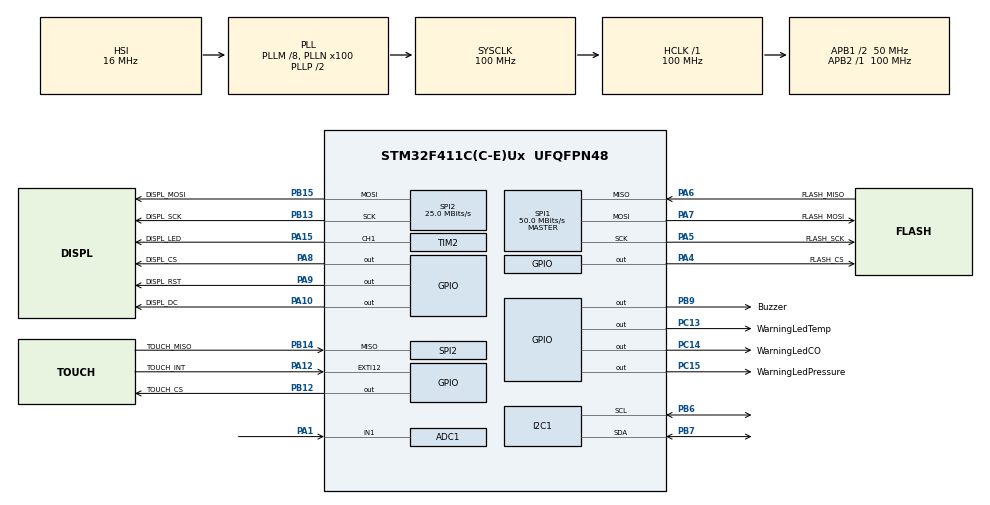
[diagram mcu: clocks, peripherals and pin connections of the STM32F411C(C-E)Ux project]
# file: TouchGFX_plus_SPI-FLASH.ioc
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ADC1.Channel-0\#ChannelRegularConversion=ADC_CHANNEL_1
ADC1.NbrOfConversionFlag=1
ADC1.Rank-0\#ChannelRegularConversion=1
ADC1.SamplingTime-0\#ChannelRegularConversion=ADC_SAMPLETIME_3CYCLES
ADC1.master=1
Dma.Request0=SPI2_TX
Dma.SPI2_TX.0.Direction=DMA_MEMORY_TO_PERIPH
Dma.SPI2_TX.0.FIFOMode=DMA_FIFOMODE_DISABLE
Dma.SPI2_TX.0.Instance=DMA1_Stream4
Dma.SPI2_TX.0.MemDataAlignment=DMA_MDATAALIGN_BYTE
Dma.SPI2_TX.0.MemInc=DMA_MINC_ENABLE
Dma.SPI2_TX.0.Mode=DMA_NORMAL
Dma.SPI2_TX.0.PeriphDataAlignment=DMA_PDATAALIGN_BYTE
Dma.SPI2_TX.0.PeriphInc=DMA_PINC_DISABLE
Dma.SPI2_TX.0.Priority=DMA_PRIORITY_LOW
Mcu.Family=STM32F4
Mcu.Name=STM32F411C(C-E)Ux
Mcu.Package=UFQFPN48
NVIC.DMA1_Stream4_IRQn=true\:0\:0\:false\:false\:true\:false\:true\:true
NVIC.EXTI15_10_IRQn=true\:0\:0\:false\:false\:true\:true\:true\:true
NVIC.PriorityGroup=NVIC_PRIORITYGROUP_4
NVIC.SPI2_IRQn=true\:0\:0\:false\:false\:true\:true\:true\:true
NVIC.TIM3_IRQn=true\:0\:0\:false\:false\:true\:true\:true\:true
PA1.Signal=ADCx_IN1
PA10.GPIO_Label=DISPL_DC
PA10.GPIO_Speed=GPIO_SPEED_FREQ_HIGH
PA10.Signal=GPIO_Output
PA12.GPIO_Label=TOUCH_INT
PA12.Signal=GPXTI12
PA13.Mode=Serial_Wire
PA13.Signal=SYS_JTMS-SWDIO
PA14.Mode=Serial_Wire
PA14.Signal=SYS_JTCK-SWCLK
PA15.GPIO_Label=DISPL_LED
PA15.Signal=S_TIM2_CH1_ETR
PA4.GPIO_Label=FLASH_CS
PA4.GPIO_Speed=GPIO_SPEED_FREQ_HIGH
PA4.PinState=GPIO_PIN_SET
PA4.Signal=GPIO_Output
PA5.GPIO_Label=FLASH_SCK
PA5.Mode=Full_Duplex_Master
PA5.Signal=SPI1_SCK
PA6.GPIO_Label=FLASH_MISO
PA6.Mode=Full_Duplex_Master
PA6.Signal=SPI1_MISO
PA7.GPIO_Label=FLASH_MOSI
PA7.Mode=Full_Duplex_Master
PA7.Signal=SPI1_MOSI
PA8.GPIO_Label=DISPL_CS
PA8.GPIO_Speed=GPIO_SPEED_FREQ_HIGH
PA8.PinState=GPIO_PIN_SET
PA8.Signal=GPIO_Output
PA9.GPIO_Label=DISPL_RST
PA9.GPIO_Speed=GPIO_SPEED_FREQ_LOW
PA9.PinState=GPIO_PIN_RESET
PA9.Signal=GPIO_Output
PB12.GPIO_Label=TOUCH_CS
PB12.GPIO_Speed=GPIO_SPEED_FREQ_HIGH
PB12.PinState=GPIO_PIN_SET
PB12.Signal=GPIO_Output
PB13.GPIO_Label=DISPL_SCK
PB13.Mode=Full_Duplex_Master
PB13.Signal=SPI2_SCK
PB14.GPIO_Label=TOUCH_MISO
PB14.Mode=Full_Duplex_Master
PB14.Signal=SPI2_MISO
PB15.GPIO_Label=DISPL_MOSI
PB15.Mode=Full_Duplex_Master
PB15.Signal=SPI2_MOSI
PB6.Mode=I2C
PB6.Signal=I2C1_SCL
PB7.Mode=I2C
PB7.Signal=I2C1_SDA
PB9.GPIO_Label=Buzzer
PB9.Signal=GPIO_Output
PC13-ANTI_TAMP.GPIO_Label=WarningLedTemp
PC13-ANTI_TAMP.Signal=GPIO_Output
PC14-OSC32_IN.GPIO_Label=WarningLedCO
PC14-OSC32_IN.Signal=GPIO_Output
PC15-OSC32_OUT.GPIO_Label=WarningLedPressure
PC15-OSC32_OUT.Signal=GPIO_Output
PH0\ -\ OSC_IN.Mode=HSE-External-Oscillator
PH0\ -\ OSC_IN.Signal=RCC_OSC_IN
PH1\ -\ OSC_OUT.Mode=HSE-External-Oscillator
PH1\ -\ OSC_OUT.Signal=RCC_OSC_OUT
ProjectManager.HeapSize=0x200
ProjectManager.StackSize=0x400
ProjectManager.TargetToolchain=STM32CubeIDE
RCC.48MHZClocksFreq_Value=50000000
RCC.AHBFreq_Value=100000000
RCC.APB1CLKDivider=RCC_HCLK_DIV2
RCC.APB1Freq_Value=50000000
RCC.APB1TimFreq_Value=100000000
RCC.APB2Freq_Value=100000000
RCC.APB2TimFreq_Value=100000000
RCC.CortexFreq_Value=100000000
RCC.HCLKFreq_Value=100000000
RCC.HSE_VALUE=25000000
RCC.HSI_VALUE=16000000
RCC.LSE_VALUE=32768
RCC.PLLM=8
RCC.PLLN=100
RCC.SYSCLKFreq_VALUE=100000000
RCC.SYSCLKSource=RCC_SYSCLKSOURCE_PLLCLK
RCC.VCOOutputFreq_Value=200000000
SH.ADCx_IN1.0=ADC1_IN1,IN1
SH.S_TIM2_CH1_ETR.0=TIM2_CH1,PWM Generation1 CH1
SPI1.CalculateBaudRate=50.0 MBits/s
SPI1.Direction=SPI_DIRECTION_2LINES
SPI1.Mode=SPI_MODE_MASTER
SPI1.VirtualType=VM_MASTER
SPI2.CalculateBaudRate=25.0 MBits/s
SPI2.Direction=SPI_DIRECTION_2LINES
SPI2.Mode=SPI_MODE_MASTER
SPI2.VirtualType=VM_MASTER
STMicroelectronics.X-CUBE-TOUCHGFX.4.22.0.ApplicationCcGraphicsJjApplication=TouchGFXOoGenerator
STMicroelectronics.X-CUBE-TOUCHGFX.4.22.0.tgfx_buffering_strategy=Partial
STMicroelectronics.X-CUBE-TOUCHGFX.4.22.0.tgfx_custom_height=240
STMicroelectronics.X-CUBE-TOUCHGFX.4.22.0.tgfx_custom_width=320
STMicroelectronics.X-CUBE-TOUCHGFX.4.22.0.tgfx_datareader=Enabled
STMicroelectronics.X-CUBE-TOUCHGFX.4.22.0.tgfx_datareader_mem_size=16777216
STMicroelectronics.X-CUBE-TOUCHGFX.4.22.0_IsPackSelfContextualization=true
TIM2.Channel-PWM\ Generation1\ CH1=TIM_CHANNEL_1
TIM2.Period=100
TIM2.Prescaler=1000
TIM3.Period=100
TIM3.Prescaler=13333
VP_CRC_VS_CRC.Mode=CRC_Activate
VP_STMicroelectronics.X-CUBE-TOUCHGFX_VS_GraphicsJjApplication_4.22.0.Mode=GraphicsJjApplication
VP_TIM3_VS_ClockSourceINT.Mode=Internal
board=custom

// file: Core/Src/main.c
/* USER CODE BEGIN Header */
/**
  ******************************************************************************
  * @file           : main.c
  * @brief          : Main program body
  ******************************************************************************
  * @attention
  *
  * Copyright (c) 2023 STMicroelectronics.
  * All rights reserved.
  *
  * This software is licensed under terms that can be found in the LICENSE file
  * in the root directory of this software component.
  * If no LICENSE file comes with this software, it is provided AS-IS.
  *
  ******************************************************************************
  */
/* USER CODE END Header */
#include "main.h"
#include "app_touchgfx.h"

ADC_HandleTypeDef hadc1;

CRC_HandleTypeDef hcrc;

I2C_HandleTypeDef hi2c1;

SPI_HandleTypeDef hspi1;
SPI_HandleTypeDef hspi2;
DMA_HandleTypeDef hdma_spi2_tx;

TIM_HandleTypeDef htim2;
TIM_HandleTypeDef htim3;

void SystemClock_Config(void);
static void MX_GPIO_Init(void);
static void MX_DMA_Init(void);
static void MX_CRC_Init(void);
static void MX_SPI1_Init(void);
static void MX_SPI2_Init(void);
static void MX_TIM2_Init(void);
static void MX_TIM3_Init(void);
static void MX_ADC1_Init(void);
static void MX_I2C1_Init(void);

int main(void)
{

  /* MCU Configuration--------------------------------------------------------*/

  /* Reset of all peripherals, Initializes the Flash interface and the Systick. */
  HAL_Init();

  /* Configure the system clock */
  SystemClock_Config();

  /* Initialize all configured peripherals */
  MX_GPIO_Init();
  MX_DMA_Init();
  MX_CRC_Init();
  MX_SPI1_Init();
  MX_SPI2_Init();
  MX_TIM2_Init();
  MX_TIM3_Init();
  MX_ADC1_Init();
  MX_I2C1_Init();
  MX_TouchGFX_Init();
  /* USER CODE BEGIN 2 */
  Displ_Init(Displ_Orientat_0);			// initialize display controller - set orientation parameter as per TouchGFX setup
  Displ_BackLight('I');  					// initialize backlight
  HAL_TIM_Base_Start_IT(&TGFX_T);			// start TouchGFX tick timer

  /* USER CODE END 2 */

  /* Infinite loop */
  while (1)
  {

  MX_TouchGFX_Process();
  }
}

void SystemClock_Config(void)
{
  RCC_OscInitTypeDef RCC_OscInitStruct = {0};
  RCC_ClkInitTypeDef RCC_ClkInitStruct = {0};

  /** Configure the main internal regulator output voltage
  */
  __HAL_RCC_PWR_CLK_ENABLE();
  __HAL_PWR_VOLTAGESCALING_CONFIG(PWR_REGULATOR_VOLTAGE_SCALE1);

  /** Initializes the RCC Oscillators according to the specified parameters
  * in the RCC_OscInitTypeDef structure.
  */
  RCC_OscInitStruct.OscillatorType = RCC_OSCILLATORTYPE_HSI;
  RCC_OscInitStruct.HSIState = RCC_HSI_ON;
  RCC_OscInitStruct.HSICalibrationValue = RCC_HSICALIBRATION_DEFAULT;
  RCC_OscInitStruct.PLL.PLLState = RCC_PLL_ON;
  RCC_OscInitStruct.PLL.PLLSource = RCC_PLLSOURCE_HSI;
  RCC_OscInitStruct.PLL.PLLM = 8;
  RCC_OscInitStruct.PLL.PLLN = 100;
  RCC_OscInitStruct.PLL.PLLP = RCC_PLLP_DIV2;
  RCC_OscInitStruct.PLL.PLLQ = 4;
  if (HAL_RCC_OscConfig(&RCC_OscInitStruct) != HAL_OK)
  {
    Error_Handler();
  }

  /** Initializes the CPU, AHB and APB buses clocks
  */
  RCC_ClkInitStruct.ClockType = RCC_CLOCKTYPE_HCLK|RCC_CLOCKTYPE_SYSCLK
                              |RCC_CLOCKTYPE_PCLK1|RCC_CLOCKTYPE_PCLK2;
  RCC_ClkInitStruct.SYSCLKSource = RCC_SYSCLKSOURCE_PLLCLK;
  RCC_ClkInitStruct.AHBCLKDivider = RCC_SYSCLK_DIV1;
  RCC_ClkInitStruct.APB1CLKDivider = RCC_HCLK_DIV2;
  RCC_ClkInitStruct.APB2CLKDivider = RCC_HCLK_DIV1;

  if (HAL_RCC_ClockConfig(&RCC_ClkInitStruct, FLASH_LATENCY_3) != HAL_OK)
  {
    Error_Handler();
  }
}

static void MX_ADC1_Init(void)
{

  ADC_ChannelConfTypeDef sConfig = {0};

  /** Configure the global features of the ADC (Clock, Resolution, Data Alignment and number of conversion)
  */
  hadc1.Instance = ADC1;
  hadc1.Init.ClockPrescaler = ADC_CLOCK_SYNC_PCLK_DIV4;
  hadc1.Init.Resolution = ADC_RESOLUTION_12B;
  hadc1.Init.ScanConvMode = DISABLE;
  hadc1.Init.ContinuousConvMode = DISABLE;
  hadc1.Init.DiscontinuousConvMode = DISABLE;
  hadc1.Init.ExternalTrigConvEdge = ADC_EXTERNALTRIGCONVEDGE_NONE;
  hadc1.Init.ExternalTrigConv = ADC_SOFTWARE_START;
  hadc1.Init.DataAlign = ADC_DATAALIGN_RIGHT;
  hadc1.Init.NbrOfConversion = 1;
  hadc1.Init.DMAContinuousRequests = DISABLE;
  hadc1.Init.EOCSelection = ADC_EOC_SINGLE_CONV;
  if (HAL_ADC_Init(&hadc1) != HAL_OK)
  {
    Error_Handler();
  }

  /** Configure for the selected ADC regular channel its corresponding rank in the sequencer and its sample time.
  */
  sConfig.Channel = ADC_CHANNEL_1;
  sConfig.Rank = 1;
  sConfig.SamplingTime = ADC_SAMPLETIME_3CYCLES;
  if (HAL_ADC_ConfigChannel(&hadc1, &sConfig) != HAL_OK)
  {
    Error_Handler();
  }

}

static void MX_CRC_Init(void)
{

  hcrc.Instance = CRC;
  if (HAL_CRC_Init(&hcrc) != HAL_OK)
  {
    Error_Handler();
  }

}

static void MX_I2C1_Init(void)
{

  hi2c1.Instance = I2C1;
  hi2c1.Init.ClockSpeed = 100000;
  hi2c1.Init.DutyCycle = I2C_DUTYCYCLE_2;
  hi2c1.Init.OwnAddress1 = 0;
  hi2c1.Init.AddressingMode = I2C_ADDRESSINGMODE_7BIT;
  hi2c1.Init.DualAddressMode = I2C_DUALADDRESS_DISABLE;
  hi2c1.Init.OwnAddress2 = 0;
  hi2c1.Init.GeneralCallMode = I2C_GENERALCALL_DISABLE;
  hi2c1.Init.NoStretchMode = I2C_NOSTRETCH_DISABLE;
  if (HAL_I2C_Init(&hi2c1) != HAL_OK)
  {
    Error_Handler();
  }

}

static void MX_SPI1_Init(void)
{

  /* SPI1 parameter configuration*/
  hspi1.Instance = SPI1;
  hspi1.Init.Mode = SPI_MODE_MASTER;
  hspi1.Init.Direction = SPI_DIRECTION_2LINES;
  hspi1.Init.DataSize = SPI_DATASIZE_8BIT;
  hspi1.Init.CLKPolarity = SPI_POLARITY_LOW;
  hspi1.Init.CLKPhase = SPI_PHASE_1EDGE;
  hspi1.Init.NSS = SPI_NSS_SOFT;
  hspi1.Init.BaudRatePrescaler = SPI_BAUDRATEPRESCALER_2;
  hspi1.Init.FirstBit = SPI_FIRSTBIT_MSB;
  hspi1.Init.TIMode = SPI_TIMODE_DISABLE;
  hspi1.Init.CRCCalculation = SPI_CRCCALCULATION_DISABLE;
  hspi1.Init.CRCPolynomial = 10;
  if (HAL_SPI_Init(&hspi1) != HAL_OK)
  {
    Error_Handler();
  }

}

static void MX_SPI2_Init(void)
{

  /* SPI2 parameter configuration*/
  hspi2.Instance = SPI2;
  hspi2.Init.Mode = SPI_MODE_MASTER;
  hspi2.Init.Direction = SPI_DIRECTION_2LINES;
  hspi2.Init.DataSize = SPI_DATASIZE_8BIT;
  hspi2.Init.CLKPolarity = SPI_POLARITY_LOW;
  hspi2.Init.CLKPhase = SPI_PHASE_1EDGE;
  hspi2.Init.NSS = SPI_NSS_SOFT;
  hspi2.Init.BaudRatePrescaler = SPI_BAUDRATEPRESCALER_2;
  hspi2.Init.FirstBit = SPI_FIRSTBIT_MSB;
  hspi2.Init.TIMode = SPI_TIMODE_DISABLE;
  hspi2.Init.CRCCalculation = SPI_CRCCALCULATION_DISABLE;
  hspi2.Init.CRCPolynomial = 10;
  if (HAL_SPI_Init(&hspi2) != HAL_OK)
  {
    Error_Handler();
  }

}

static void MX_TIM2_Init(void)
{

  TIM_MasterConfigTypeDef sMasterConfig = {0};
  TIM_OC_InitTypeDef sConfigOC = {0};

  htim2.Instance = TIM2;
  htim2.Init.Prescaler = 1000;
  htim2.Init.CounterMode = TIM_COUNTERMODE_UP;
  htim2.Init.Period = 100;
  htim2.Init.ClockDivision = TIM_CLOCKDIVISION_DIV1;
  htim2.Init.AutoReloadPreload = TIM_AUTORELOAD_PRELOAD_DISABLE;
  if (HAL_TIM_PWM_Init(&htim2) != HAL_OK)
  {
    Error_Handler();
  }
  sMasterConfig.MasterOutputTrigger = TIM_TRGO_RESET;
  sMasterConfig.MasterSlaveMode = TIM_MASTERSLAVEMODE_DISABLE;
  if (HAL_TIMEx_MasterConfigSynchronization(&htim2, &sMasterConfig) != HAL_OK)
  {
    Error_Handler();
  }
  sConfigOC.OCMode = TIM_OCMODE_PWM1;
  sConfigOC.Pulse = 0;
  sConfigOC.OCPolarity = TIM_OCPOLARITY_HIGH;
  sConfigOC.OCFastMode = TIM_OCFAST_DISABLE;
  if (HAL_TIM_PWM_ConfigChannel(&htim2, &sConfigOC, TIM_CHANNEL_1) != HAL_OK)
  {
    Error_Handler();
  }
  HAL_TIM_MspPostInit(&htim2);

}

static void MX_TIM3_Init(void)
{

  TIM_ClockConfigTypeDef sClockSourceConfig = {0};
  TIM_MasterConfigTypeDef sMasterConfig = {0};

  htim3.Instance = TIM3;
  htim3.Init.Prescaler = 13333;
  htim3.Init.CounterMode = TIM_COUNTERMODE_UP;
  htim3.Init.Period = 100;
  htim3.Init.ClockDivision = TIM_CLOCKDIVISION_DIV1;
  htim3.Init.AutoReloadPreload = TIM_AUTORELOAD_PRELOAD_DISABLE;
  if (HAL_TIM_Base_Init(&htim3) != HAL_OK)
  {
    Error_Handler();
  }
  sClockSourceConfig.ClockSource = TIM_CLOCKSOURCE_INTERNAL;
  if (HAL_TIM_ConfigClockSource(&htim3, &sClockSourceConfig) != HAL_OK)
  {
    Error_Handler();
  }
  sMasterConfig.MasterOutputTrigger = TIM_TRGO_RESET;
  sMasterConfig.MasterSlaveMode = TIM_MASTERSLAVEMODE_DISABLE;
  if (HAL_TIMEx_MasterConfigSynchronization(&htim3, &sMasterConfig) != HAL_OK)
  {
    Error_Handler();
  }

}

static void MX_DMA_Init(void)
{

  /* DMA controller clock enable */
  __HAL_RCC_DMA1_CLK_ENABLE();

  /* DMA interrupt init */
  /* DMA1_Stream4_IRQn interrupt configuration */
  HAL_NVIC_SetPriority(DMA1_Stream4_IRQn, 0, 0);
  HAL_NVIC_EnableIRQ(DMA1_Stream4_IRQn);

}

static void MX_GPIO_Init(void)
{
  GPIO_InitTypeDef GPIO_InitStruct = {0};

  /* GPIO Ports Clock Enable */
  __HAL_RCC_GPIOC_CLK_ENABLE();
  __HAL_RCC_GPIOH_CLK_ENABLE();
  __HAL_RCC_GPIOA_CLK_ENABLE();
  __HAL_RCC_GPIOB_CLK_ENABLE();

  /*Configure GPIO pin Output Level */
  HAL_GPIO_WritePin(GPIOC, WarningLedTemp_Pin|WarningLedCO_Pin|WarningLedPressure_Pin, GPIO_PIN_RESET);

  /*Configure GPIO pin Output Level */
  HAL_GPIO_WritePin(GPIOA, FLASH_CS_Pin|DISPL_CS_Pin, GPIO_PIN_SET);

  /*Configure GPIO pin Output Level */
  HAL_GPIO_WritePin(TOUCH_CS_GPIO_Port, TOUCH_CS_Pin, GPIO_PIN_SET);

  /*Configure GPIO pin Output Level */
  HAL_GPIO_WritePin(GPIOA, DISPL_RST_Pin|DISPL_DC_Pin, GPIO_PIN_RESET);

  /*Configure GPIO pin Output Level */
  HAL_GPIO_WritePin(Buzzer_GPIO_Port, Buzzer_Pin, GPIO_PIN_RESET);

  /*Configure GPIO pins : WarningLedTemp_Pin WarningLedCO_Pin WarningLedPressure_Pin */
  GPIO_InitStruct.Pin = WarningLedTemp_Pin|WarningLedCO_Pin|WarningLedPressure_Pin;
  GPIO_InitStruct.Mode = GPIO_MODE_OUTPUT_PP;
  GPIO_InitStruct.Pull = GPIO_NOPULL;
  GPIO_InitStruct.Speed = GPIO_SPEED_FREQ_LOW;
  HAL_GPIO_Init(GPIOC, &GPIO_InitStruct);

  /*Configure GPIO pins : FLASH_CS_Pin DISPL_CS_Pin DISPL_DC_Pin */
  GPIO_InitStruct.Pin = FLASH_CS_Pin|DISPL_CS_Pin|DISPL_DC_Pin;
  GPIO_InitStruct.Mode = GPIO_MODE_OUTPUT_PP;
  GPIO_InitStruct.Pull = GPIO_NOPULL;
  GPIO_InitStruct.Speed = GPIO_SPEED_FREQ_HIGH;
  HAL_GPIO_Init(GPIOA, &GPIO_InitStruct);

  /*Configure GPIO pin : TOUCH_CS_Pin */
  GPIO_InitStruct.Pin = TOUCH_CS_Pin;
  GPIO_InitStruct.Mode = GPIO_MODE_OUTPUT_PP;
  GPIO_InitStruct.Pull = GPIO_NOPULL;
  GPIO_InitStruct.Speed = GPIO_SPEED_FREQ_HIGH;
  HAL_GPIO_Init(TOUCH_CS_GPIO_Port, &GPIO_InitStruct);

  /*Configure GPIO pin : DISPL_RST_Pin */
  GPIO_InitStruct.Pin = DISPL_RST_Pin;
  GPIO_InitStruct.Mode = GPIO_MODE_OUTPUT_PP;
  GPIO_InitStruct.Pull = GPIO_NOPULL;
  GPIO_InitStruct.Speed = GPIO_SPEED_FREQ_LOW;
  HAL_GPIO_Init(DISPL_RST_GPIO_Port, &GPIO_InitStruct);

  /*Configure GPIO pin : TOUCH_INT_Pin */
  GPIO_InitStruct.Pin = TOUCH_INT_Pin;
  GPIO_InitStruct.Mode = GPIO_MODE_IT_RISING;
  GPIO_InitStruct.Pull = GPIO_NOPULL;
  HAL_GPIO_Init(TOUCH_INT_GPIO_Port, &GPIO_InitStruct);

  /*Configure GPIO pin : Buzzer_Pin */
  GPIO_InitStruct.Pin = Buzzer_Pin;
  GPIO_InitStruct.Mode = GPIO_MODE_OUTPUT_PP;
  GPIO_InitStruct.Pull = GPIO_NOPULL;
  GPIO_InitStruct.Speed = GPIO_SPEED_FREQ_LOW;
  HAL_GPIO_Init(Buzzer_GPIO_Port, &GPIO_InitStruct);

  /* EXTI interrupt init*/
  HAL_NVIC_SetPriority(EXTI15_10_IRQn, 0, 0);
  HAL_NVIC_EnableIRQ(EXTI15_10_IRQn);

}

void Error_Handler(void)
{
  __disable_irq();
  while (1)
  {
  }
}
